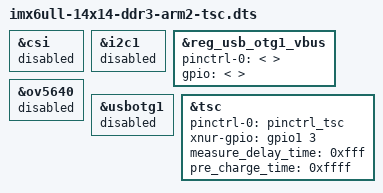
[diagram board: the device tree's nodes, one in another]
/*
 * Copyright (C) 2016 Freescale Semiconductor, Inc.
 *
 * This program is free software; you can redistribute it and/or modify
 * it under the terms of the GNU General Public License version 2 as
 * published by the Free Software Foundation.
 */

#include "imx6ull-14x14-ddr3-arm2-lcdif.dts"

&csi {
	status = "disabled";
};

&i2c1 {
	status = "disabled";
};

&reg_usb_otg1_vbus {
	pinctrl-0 = < >;
	gpio = < >;
};

&ov5640 {
	status = "disabled";
};

&usbotg1 {
	status = "disabled";
};

&tsc {
	pinctrl-names = "default";
	pinctrl-0 = <&pinctrl_tsc>;
	status = "okay";
	xnur-gpio = <&gpio1 3 0>;
	measure_delay_time = <0xfff>;
	pre_charge_time = <0xffff>;
};
